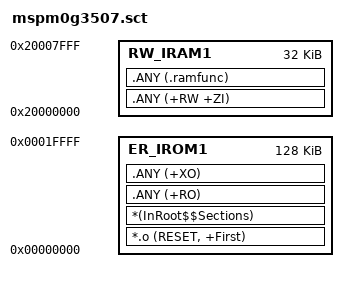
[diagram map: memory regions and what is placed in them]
; *************************************************************
; *** Scatter-Loading Description File generated by uVision ***
; *************************************************************

LR_IROM1 0x00000000 0x00020000  {    ; load region size_region
  ER_IROM1 0x00000000 ALIGNALL 8 0x00020000  {  ; load address = execution address
   *.o (RESET, +First)
   *(InRoot$$Sections)
   .ANY (+RO)
   .ANY (+XO)
  }
  RW_IRAM1 0x20000000 0x00008000  {  ; RW data
   .ANY (+RW +ZI)
   .ANY (.ramfunc)
  }
}

; BCR/BSL 配置段已注释 — 这些地址在 0x41C00000 (NONMAIN flash),
; BSL 烧录器写不进去会报"8 字节对齐"错误(实际是地址范围不合法)
; 项目代码没引用 .BCRConfig / .BSLConfig,删掉不影响应用
; 后续若需要配置 BSL 行为(如改密码),用 UniFlash 单独烧 .bin 到这两个地址
; LR_BCR 0x41C00000 0x00000100  {    ; load region size_region
;   BCR_CONFIG 0x41C00000 0x00000080{
;	.ANY (.BCRConfig)
;   }
; }
;
; LR_BSL 0x41C00100 0x00000100  {    ; load region size_region
;    BSL_CONFIG 0x41C00100 0x00000080{
;	.ANY (.BSLConfig)
;   }
; }
